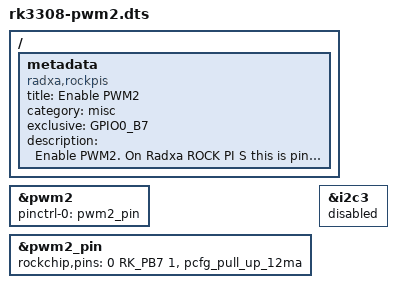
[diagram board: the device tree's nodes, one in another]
/dts-v1/;
/plugin/;

#include <dt-bindings/pinctrl/rockchip.h>

/ {
	metadata {
		title = "Enable PWM2";
		compatible = "radxa,rockpis", "radxa,rock-s0";
		category = "misc";
		exclusive = "GPIO0_B7";
		description = "Enable PWM2.
On Radxa ROCK PI S this is pin 11.
On ROCK S0 this is pin 27.";
	};
};

&pwm2 {
	status = "okay";
	pinctrl-names = "default";
	pinctrl-0 = <&pwm2_pin>;
};

&pwm2_pin {
	rockchip,pins =
		<0 RK_PB7 1 &pcfg_pull_up_12ma>;
};

&i2c3 {
	status = "disabled";
};
